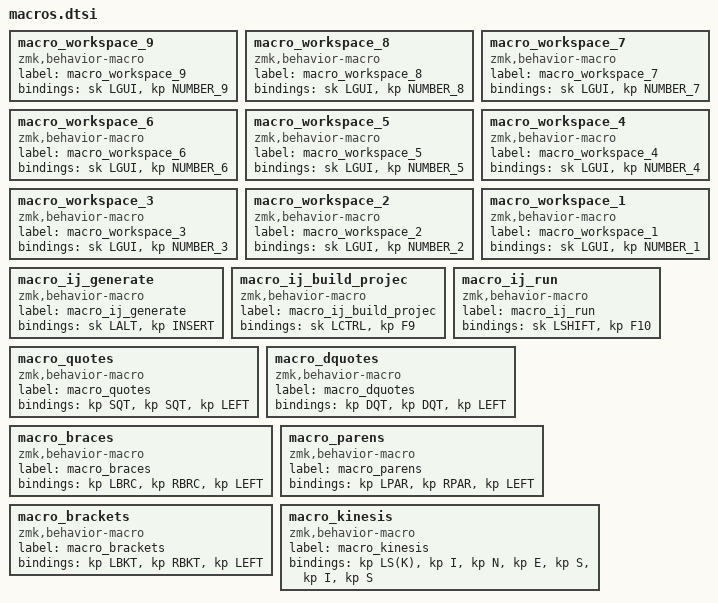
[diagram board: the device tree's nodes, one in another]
macro_workspace_9: macro_workspace_9{
compatible = "zmk,behavior-macro";
label = "macro_workspace_9";
#binding-cells = <0>;
bindings = <&sk LGUI>, <&kp NUMBER_9>;
};
macro_workspace_8: macro_workspace_8{
compatible = "zmk,behavior-macro";
label = "macro_workspace_8";
#binding-cells = <0>;
bindings = <&sk LGUI>, <&kp NUMBER_8>;
};
macro_workspace_7: macro_workspace_7{
compatible = "zmk,behavior-macro";
label = "macro_workspace_7";
#binding-cells = <0>;
bindings = <&sk LGUI>, <&kp NUMBER_7>;
};
macro_workspace_6: macro_workspace_6{
compatible = "zmk,behavior-macro";
label = "macro_workspace_6";
#binding-cells = <0>;
bindings = <&sk LGUI>, <&kp NUMBER_6>;
};
macro_workspace_5: macro_workspace_5{
compatible = "zmk,behavior-macro";
label = "macro_workspace_5";
#binding-cells = <0>;
bindings = <&sk LGUI>, <&kp NUMBER_5>;
};
macro_workspace_4: macro_workspace_4{
compatible = "zmk,behavior-macro";
label = "macro_workspace_4";
#binding-cells = <0>;
bindings = <&sk LGUI>, <&kp NUMBER_4>;
};
macro_workspace_3: macro_workspace_3{
compatible = "zmk,behavior-macro";
label = "macro_workspace_3";
#binding-cells = <0>;
bindings = <&sk LGUI>, <&kp NUMBER_3>;
};
macro_workspace_2: macro_workspace_2{
compatible = "zmk,behavior-macro";
label = "macro_workspace_2";
#binding-cells = <0>;
bindings = <&sk LGUI>, <&kp NUMBER_2>;
};
macro_workspace_1: macro_workspace_1{
compatible = "zmk,behavior-macro";
label = "macro_workspace_1";
#binding-cells = <0>;
bindings = <&sk LGUI>, <&kp NUMBER_1>;
};
macro_ij_generate: macro_ij_generate{
compatible = "zmk,behavior-macro";
label = "macro_ij_generate";
#binding-cells = <0>;
bindings = <&sk LALT>, <&kp INSERT>;
};
macro_ij_build_projec: macro_ij_build_projec{
compatible = "zmk,behavior-macro";
label = "macro_ij_build_projec";
#binding-cells = <0>;
bindings = <&sk LCTRL>, <&kp F9>;
};
macro_ij_run: macro_ij_run{
compatible = "zmk,behavior-macro";
label = "macro_ij_run";
#binding-cells = <0>;
bindings = <&sk LSHIFT>, <&kp F10>;
};
macro_quotes: macro_quotes{
compatible = "zmk,behavior-macro";
label = "macro_quotes";
#binding-cells = <0>;
bindings = <&kp SQT>, <&kp SQT>, <&kp LEFT>;
};
macro_dquotes: macro_dquotes{
compatible = "zmk,behavior-macro";
label = "macro_dquotes";
#binding-cells = <0>;
bindings = <&kp DQT>, <&kp DQT>, <&kp LEFT>;
};
macro_braces: macro_braces{
compatible = "zmk,behavior-macro";
label = "macro_braces";
#binding-cells = <0>;
bindings = <&kp LBRC>, <&kp RBRC>, <&kp LEFT>;
};
macro_parens: macro_parens{
compatible = "zmk,behavior-macro";
label = "macro_parens";
#binding-cells = <0>;
bindings = <&kp LPAR>, <&kp RPAR>, <&kp LEFT>;
};
macro_brackets: macro_brackets{
compatible = "zmk,behavior-macro";
label = "macro_brackets";
#binding-cells = <0>;
bindings = <&kp LBKT>, <&kp RBKT>, <&kp LEFT>;
};
macro_kinesis: macro_kinesis{
compatible = "zmk,behavior-macro";
label = "macro_kinesis";
#binding-cells = <0>;
bindings = <&kp LS(K)>, <&kp I>, <&kp N>, <&kp E>, <&kp S>, <&kp I>, <&kp S>;
};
